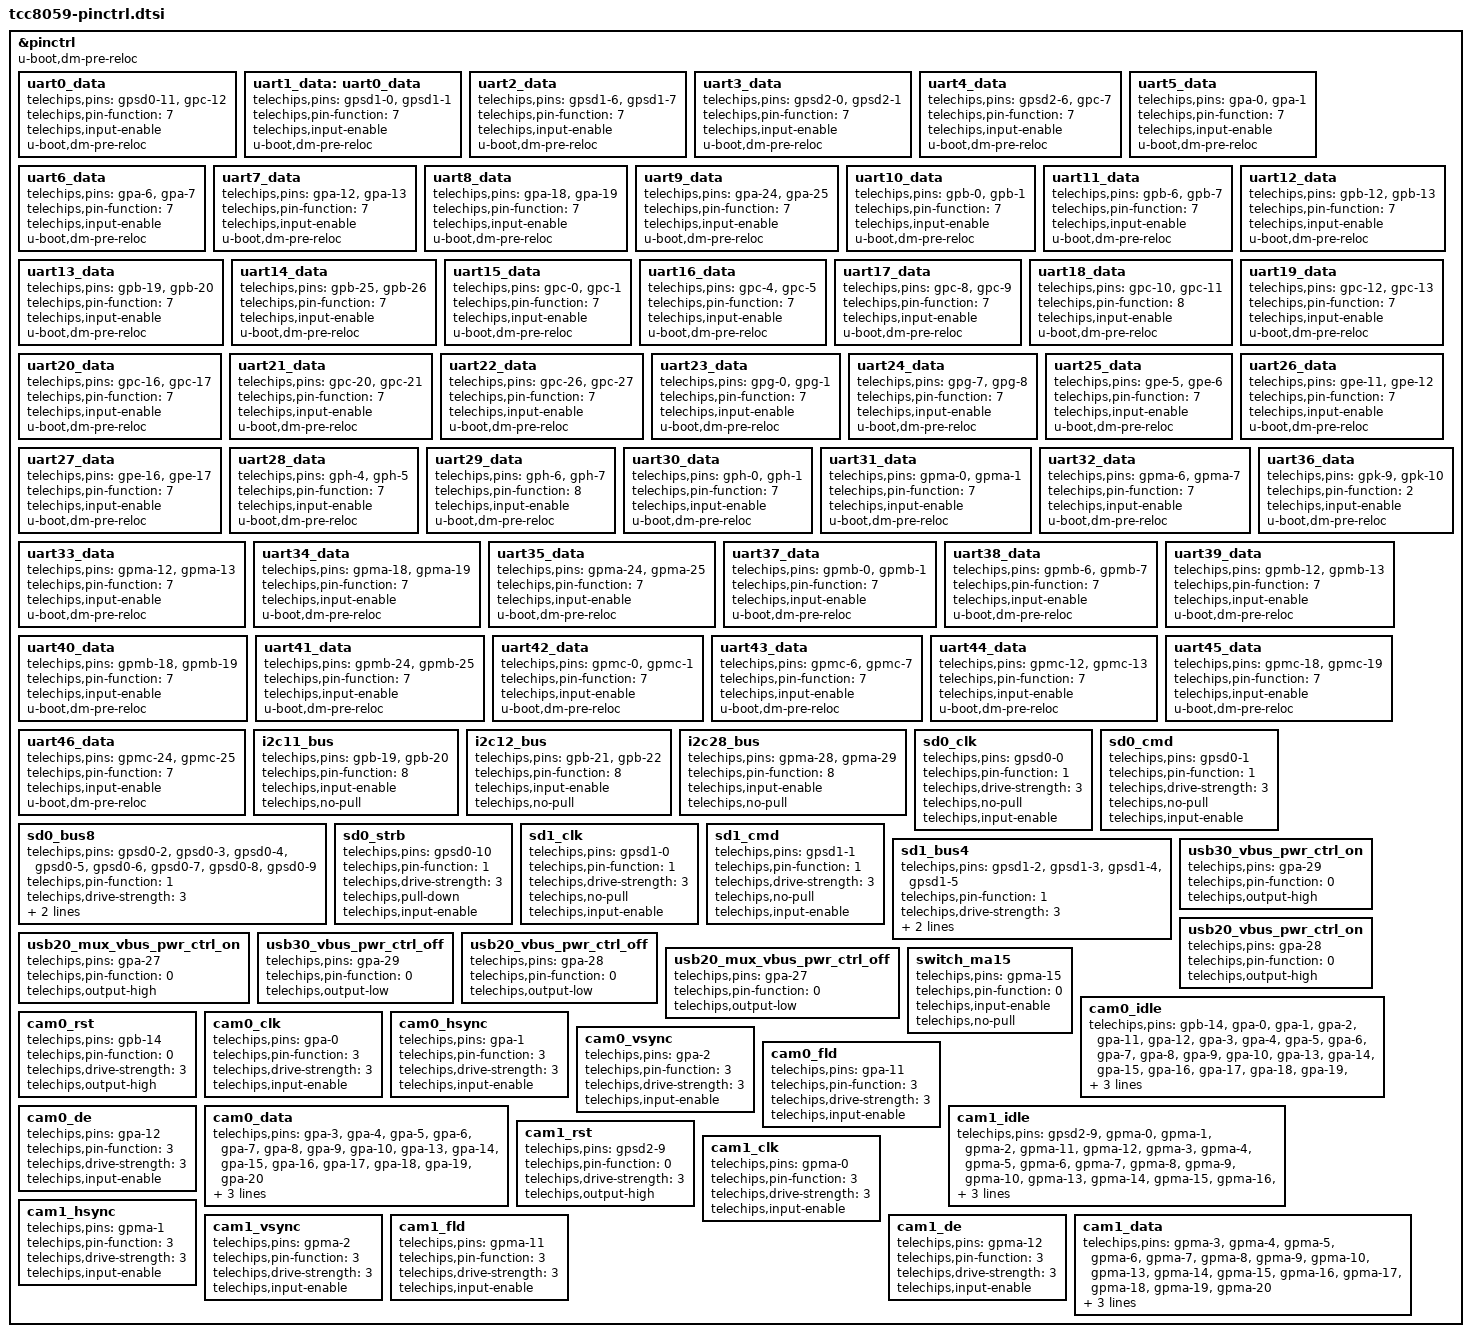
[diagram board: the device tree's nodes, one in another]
// SPDX-License-Identifier: (GPL-2.0-or-later OR MIT)
/*
 * Copyright (C) Telechips Inc.
 */

&pinctrl {
	u-boot,dm-pre-reloc;

	/omit-if-no-ref/
	uart0_data: uart0_data {
		telechips,pins = "gpsd0-11", "gpc-12";
		telechips,pin-function = <7>;
		telechips,input-enable;
		u-boot,dm-pre-reloc;
	};

	/omit-if-no-ref/
	uart1_data: uart0_data {
		telechips,pins = "gpsd1-0", "gpsd1-1";
		telechips,pin-function = <7>;
		telechips,input-enable;
		u-boot,dm-pre-reloc;
	};

	/omit-if-no-ref/
	uart2_data: uart2_data {
		telechips,pins = "gpsd1-6", "gpsd1-7";
		telechips,pin-function = <7>;
		telechips,input-enable;
		u-boot,dm-pre-reloc;
	};

	/omit-if-no-ref/
	uart3_data: uart3_data {
		telechips,pins = "gpsd2-0", "gpsd2-1";
		telechips,pin-function = <7>;
		telechips,input-enable;
		u-boot,dm-pre-reloc;
	};

	/omit-if-no-ref/
	uart4_data: uart4_data {
		telechips,pins = "gpsd2-6", "gpc-7";
		telechips,pin-function = <7>;
		telechips,input-enable;
		u-boot,dm-pre-reloc;
	};

	/omit-if-no-ref/
	uart5_data: uart5_data {
		telechips,pins = "gpa-0", "gpa-1";
		telechips,pin-function = <7>;
		telechips,input-enable;
		u-boot,dm-pre-reloc;
	};

	/omit-if-no-ref/
	uart6_data: uart6_data {
		telechips,pins = "gpa-6", "gpa-7";
		telechips,pin-function = <7>;
		telechips,input-enable;
		u-boot,dm-pre-reloc;
	};

	/omit-if-no-ref/
	uart7_data: uart7_data {
		telechips,pins = "gpa-12", "gpa-13";
		telechips,pin-function = <7>;
		telechips,input-enable;
		u-boot,dm-pre-reloc;
	};

	/omit-if-no-ref/
	uart8_data: uart8_data {
		telechips,pins = "gpa-18", "gpa-19";
		telechips,pin-function = <7>;
		telechips,input-enable;
		u-boot,dm-pre-reloc;
	};

	/omit-if-no-ref/
	uart9_data: uart9_data {
		telechips,pins = "gpa-24", "gpa-25";
		telechips,pin-function = <7>;
		telechips,input-enable;
		u-boot,dm-pre-reloc;
	};

	/omit-if-no-ref/
	uart10_data: uart10_data {
		telechips,pins = "gpb-0", "gpb-1";
		telechips,pin-function = <7>;
		telechips,input-enable;
		u-boot,dm-pre-reloc;
	};

	/omit-if-no-ref/
	uart11_data: uart11_data {
		telechips,pins = "gpb-6", "gpb-7";
		telechips,pin-function = <7>;
		telechips,input-enable;
		u-boot,dm-pre-reloc;
	};

	/omit-if-no-ref/
	uart12_data: uart12_data {
		telechips,pins = "gpb-12", "gpb-13";
		telechips,pin-function = <7>;
		telechips,input-enable;
		u-boot,dm-pre-reloc;
	};

	/omit-if-no-ref/
	uart13_data: uart13_data {
		telechips,pins = "gpb-19", "gpb-20";
		telechips,pin-function = <7>;
		telechips,input-enable;
		u-boot,dm-pre-reloc;
	};

	/omit-if-no-ref/
	uart14_data: uart14_data {
		telechips,pins = "gpb-25", "gpb-26";
		telechips,pin-function = <7>;
		telechips,input-enable;
		u-boot,dm-pre-reloc;
	};

	/omit-if-no-ref/
	uart15_data: uart15_data {
		telechips,pins = "gpc-0", "gpc-1";
		telechips,pin-function = <7>;
		telechips,input-enable;
		u-boot,dm-pre-reloc;
	};

	/omit-if-no-ref/
	uart16_data: uart16_data {
		telechips,pins = "gpc-4", "gpc-5";
		telechips,pin-function = <7>;
		telechips,input-enable;
		u-boot,dm-pre-reloc;
	};

	/omit-if-no-ref/
	uart17_data: uart17_data {
		telechips,pins = "gpc-8", "gpc-9";
		telechips,pin-function = <7>;
		telechips,input-enable;
		u-boot,dm-pre-reloc;
	};

	/omit-if-no-ref/
	uart18_data: uart18_data {
		telechips,pins = "gpc-10", "gpc-11";
		telechips,pin-function = <8>;
		telechips,input-enable;
		u-boot,dm-pre-reloc;
	};

	/omit-if-no-ref/
	uart19_data: uart19_data {
		telechips,pins = "gpc-12", "gpc-13";
		telechips,pin-function = <7>;
		telechips,input-enable;
		u-boot,dm-pre-reloc;
	};

	/omit-if-no-ref/
	uart20_data: uart20_data {
		telechips,pins = "gpc-16", "gpc-17";
		telechips,pin-function = <7>;
		telechips,input-enable;
		u-boot,dm-pre-reloc;
	};

	/omit-if-no-ref/
	uart21_data: uart21_data {
		telechips,pins = "gpc-20", "gpc-21";
		telechips,pin-function = <7>;
		telechips,input-enable;
		u-boot,dm-pre-reloc;
	};

	/omit-if-no-ref/
	uart22_data: uart22_data {
		telechips,pins = "gpc-26", "gpc-27";
		telechips,pin-function = <7>;
		telechips,input-enable;
		u-boot,dm-pre-reloc;
	};

	/omit-if-no-ref/
	uart23_data: uart23_data {
		telechips,pins = "gpg-0", "gpg-1";
		telechips,pin-function = <7>;
		telechips,input-enable;
		u-boot,dm-pre-reloc;
	};

	/omit-if-no-ref/
	uart24_data: uart24_data {
		telechips,pins = "gpg-7", "gpg-8";
		telechips,pin-function = <7>;
		telechips,input-enable;
		u-boot,dm-pre-reloc;
	};

	/omit-if-no-ref/
	uart25_data: uart25_data {
		telechips,pins = "gpe-5", "gpe-6";
		telechips,pin-function = <7>;
		telechips,input-enable;
		u-boot,dm-pre-reloc;
	};

	/omit-if-no-ref/
	uart26_data: uart26_data {
		telechips,pins = "gpe-11", "gpe-12";
		telechips,pin-function = <7>;
		telechips,input-enable;
		u-boot,dm-pre-reloc;
	};

	/omit-if-no-ref/
	uart27_data: uart27_data {
		telechips,pins = "gpe-16", "gpe-17";
		telechips,pin-function = <7>;
		telechips,input-enable;
		u-boot,dm-pre-reloc;
	};

	/omit-if-no-ref/
	uart28_data: uart28_data {
		telechips,pins = "gph-4", "gph-5";
		telechips,pin-function = <7>;
		telechips,input-enable;
		u-boot,dm-pre-reloc;
	};

	/omit-if-no-ref/
	uart29_data: uart29_data {
		telechips,pins = "gph-6", "gph-7";
		telechips,pin-function = <8>;
		telechips,input-enable;
		u-boot,dm-pre-reloc;
	};

	/omit-if-no-ref/
	uart30_data: uart30_data {
		telechips,pins = "gph-0", "gph-1";
		telechips,pin-function = <7>;
		telechips,input-enable;
		u-boot,dm-pre-reloc;
	};

	/omit-if-no-ref/
	uart31_data: uart31_data {
		telechips,pins = "gpma-0", "gpma-1";
		telechips,pin-function = <7>;
		telechips,input-enable;
		u-boot,dm-pre-reloc;
	};

	/omit-if-no-ref/
	uart32_data: uart32_data {
		telechips,pins = "gpma-6", "gpma-7";
		telechips,pin-function = <7>;
		telechips,input-enable;
		u-boot,dm-pre-reloc;
	};

	/omit-if-no-ref/
	uart33_data: uart33_data {
		telechips,pins = "gpma-12", "gpma-13";
		telechips,pin-function = <7>;
		telechips,input-enable;
		u-boot,dm-pre-reloc;
	};

	/omit-if-no-ref/
	uart34_data: uart34_data {
		telechips,pins = "gpma-18", "gpma-19";
		telechips,pin-function = <7>;
		telechips,input-enable;
		u-boot,dm-pre-reloc;
	};

	/omit-if-no-ref/
	uart35_data: uart35_data {
		telechips,pins = "gpma-24", "gpma-25";
		telechips,pin-function = <7>;
		telechips,input-enable;
		u-boot,dm-pre-reloc;
	};

	/omit-if-no-ref/
	uart36_data: uart36_data {
		telechips,pins = "gpk-9", "gpk-10";
		telechips,pin-function = <2>;
		telechips,input-enable;
		u-boot,dm-pre-reloc;
	};

	/omit-if-no-ref/
	uart37_data: uart37_data {
		telechips,pins = "gpmb-0", "gpmb-1";
		telechips,pin-function = <7>;
		telechips,input-enable;
		u-boot,dm-pre-reloc;
	};

	/omit-if-no-ref/
	uart38_data: uart38_data {
		telechips,pins = "gpmb-6", "gpmb-7";
		telechips,pin-function = <7>;
		telechips,input-enable;
		u-boot,dm-pre-reloc;
	};

	/omit-if-no-ref/
	uart39_data: uart39_data {
		telechips,pins = "gpmb-12", "gpmb-13";
		telechips,pin-function = <7>;
		telechips,input-enable;
		u-boot,dm-pre-reloc;
	};

	/omit-if-no-ref/
	uart40_data: uart40_data {
		telechips,pins = "gpmb-18", "gpmb-19";
		telechips,pin-function = <7>;
		telechips,input-enable;
		u-boot,dm-pre-reloc;
	};

	/omit-if-no-ref/
	uart41_data: uart41_data {
		telechips,pins = "gpmb-24", "gpmb-25";
		telechips,pin-function = <7>;
		telechips,input-enable;
		u-boot,dm-pre-reloc;
	};

	/omit-if-no-ref/
	uart42_data: uart42_data {
		telechips,pins = "gpmc-0", "gpmc-1";
		telechips,pin-function = <7>;
		telechips,input-enable;
		u-boot,dm-pre-reloc;
	};

	/omit-if-no-ref/
	uart43_data: uart43_data {
		telechips,pins = "gpmc-6", "gpmc-7";
		telechips,pin-function = <7>;
		telechips,input-enable;
		u-boot,dm-pre-reloc;
	};

	/omit-if-no-ref/
	uart44_data: uart44_data {
		telechips,pins = "gpmc-12", "gpmc-13";
		telechips,pin-function = <7>;
		telechips,input-enable;
		u-boot,dm-pre-reloc;
	};

	/omit-if-no-ref/
	uart45_data: uart45_data {
		telechips,pins = "gpmc-18", "gpmc-19";
		telechips,pin-function = <7>;
		telechips,input-enable;
		u-boot,dm-pre-reloc;
	};

	/omit-if-no-ref/
	uart46_data: uart46_data {
		telechips,pins = "gpmc-24", "gpmc-25";
		telechips,pin-function = <7>;
		telechips,input-enable;
		u-boot,dm-pre-reloc;
	};

	/omit-if-no-ref/
	i2c11_bus: i2c11_bus {
		telechips,pins = "gpb-19", "gpb-20";
		telechips,pin-function = <8>;
		telechips,input-enable;
		telechips,no-pull;
	};

	/omit-if-no-ref/
	i2c12_bus: i2c12_bus {
		telechips,pins = "gpb-21", "gpb-22";
		telechips,pin-function = <8>;
		telechips,input-enable;
		telechips,no-pull;
	};

	/omit-if-no-ref/
	i2c28_bus: i2c28_bus {
		telechips,pins = "gpma-28", "gpma-29";
		telechips,pin-function = <8>;
		telechips,input-enable;
		telechips,no-pull;
	};

	/* GPIO SD0 */
	/omit-if-no-ref/
	sd0_clk: sd0_clk {
		telechips,pins = "gpsd0-0";
		telechips,pin-function = <1>;
		telechips,drive-strength = <3>;
		telechips,no-pull;
		telechips,input-enable;
	};

	/omit-if-no-ref/
	sd0_cmd: sd0_cmd {
		telechips,pins = "gpsd0-1";
		telechips,pin-function = <1>;
		telechips,drive-strength = <3>;
		telechips,no-pull;
		telechips,input-enable;
	};

	/omit-if-no-ref/
	sd0_bus8: sd0_bus8 {
		telechips,pins =  "gpsd0-2", "gpsd0-3", "gpsd0-4", "gpsd0-5",
				  "gpsd0-6", "gpsd0-7", "gpsd0-8", "gpsd0-9";
		telechips,pin-function = <1>;
		telechips,drive-strength = <3>;
		telechips,no-pull;
		telechips,input-enable;
	};

	/omit-if-no-ref/
	sd0_strb: sd0_strb {
		telechips,pins = "gpsd0-10";
		telechips,pin-function = <1>;
		telechips,drive-strength = <3>;
		telechips,pull-down;
		telechips,input-enable;
	};

	/* GPIO SD1 */
	/omit-if-no-ref/
	sd1_clk: sd1_clk {
		telechips,pins = "gpsd1-0";
		telechips,pin-function = <1>;
		telechips,drive-strength = <3>;
		telechips,no-pull;
		telechips,input-enable;
	};

	/omit-if-no-ref/
	sd1_cmd: sd1_cmd {
		telechips,pins = "gpsd1-1";
		telechips,pin-function = <1>;
		telechips,drive-strength = <3>;
		telechips,no-pull;
		telechips,input-enable;
	};

	/omit-if-no-ref/
	sd1_bus4: sd1_bus4 {
		telechips,pins = "gpsd1-2", "gpsd1-3", "gpsd1-4", "gpsd1-5";
		telechips,pin-function = <1>;
		telechips,drive-strength = <3>;
		telechips,no-pull;
		telechips,input-enable;
	};

	/* GPIO USB VBUS */
	/omit-if-no-ref/
	usb30_vbus_pwr_ctrl_on: usb30_vbus_pwr_ctrl_on {
		telechips,pins = "gpa-29";
		telechips,pin-function = <0>;
		telechips,output-high;
	};

	/omit-if-no-ref/
	usb20_vbus_pwr_ctrl_on: usb20_vbus_pwr_ctrl_on {
		telechips,pins = "gpa-28";
		telechips,pin-function = <0>;
		telechips,output-high;
	};

	/omit-if-no-ref/
	usb20_mux_vbus_pwr_ctrl_on: usb20_mux_vbus_pwr_ctrl_on {
		telechips,pins = "gpa-27";
		telechips,pin-function = <0>;
		telechips,output-high;
	};

	/omit-if-no-ref/
	usb30_vbus_pwr_ctrl_off: usb30_vbus_pwr_ctrl_off {
		telechips,pins = "gpa-29";
		telechips,pin-function = <0>;
		telechips,output-low;
	};

	/omit-if-no-ref/
	usb20_vbus_pwr_ctrl_off: usb20_vbus_pwr_ctrl_off {
		telechips,pins = "gpa-28";
		telechips,pin-function = <0>;
		telechips,output-low;
	};

	/omit-if-no-ref/
	usb20_mux_vbus_pwr_ctrl_off: usb20_mux_vbus_pwr_ctrl_off {
		telechips,pins = "gpa-27";
		telechips,pin-function = <0>;
		telechips,output-low;
	};

	/omit-if-no-ref/
	switch_ma15: switch_ma15 {
		telechips,pins = "gpma-15";
		telechips,pin-function = <0>;
		telechips,input-enable;
		telechips,no-pull;
	};

	/omit-if-no-ref/
	cam0_idle: cam0_idle {
		telechips,pins = "gpb-14",
				 "gpa-0",  "gpa-1",  "gpa-2",
				 "gpa-11", "gpa-12",
				 "gpa-3",  "gpa-4",  "gpa-5",  "gpa-6",
				 "gpa-7",  "gpa-8",  "gpa-9",  "gpa-10",
				 "gpa-13", "gpa-14", "gpa-15", "gpa-16",
				 "gpa-17", "gpa-18", "gpa-19", "gpa-20";
		telechips,pin-function = <0>;
		telechips,output-low;
	};

	/omit-if-no-ref/
	cam0_rst: cam0_rst {
		telechips,pins = "gpb-14";
		telechips,pin-function = <0>;
		telechips,drive-strength = <3>;
		telechips,output-high;
	};

	/omit-if-no-ref/
	cam0_clk: cam0_clk {
		telechips,pins = "gpa-0";
		telechips,pin-function = <3>;
		telechips,drive-strength = <3>;
		telechips,input-enable;
	};

	/omit-if-no-ref/
	cam0_hsync: cam0_hsync {
		telechips,pins = "gpa-1";
		telechips,pin-function = <3>;
		telechips,drive-strength = <3>;
		telechips,input-enable;
	};

	/omit-if-no-ref/
	cam0_vsync: cam0_vsync {
		telechips,pins = "gpa-2";
		telechips,pin-function = <3>;
		telechips,drive-strength = <3>;
		telechips,input-enable;
	};

	/omit-if-no-ref/
	cam0_fld: cam0_fld {
		telechips,pins = "gpa-11";
		telechips,pin-function = <3>;
		telechips,drive-strength = <3>;
		telechips,input-enable;
	};

	/omit-if-no-ref/
	cam0_de: cam0_de {
		telechips,pins = "gpa-12";
		telechips,pin-function = <3>;
		telechips,drive-strength = <3>;
		telechips,input-enable;
	};

	/omit-if-no-ref/
	cam0_data: cam0_data {
		telechips,pins = "gpa-3",  "gpa-4",  "gpa-5",  "gpa-6",
				 "gpa-7",  "gpa-8",  "gpa-9",  "gpa-10",
				 "gpa-13", "gpa-14", "gpa-15", "gpa-16",
				 "gpa-17", "gpa-18", "gpa-19", "gpa-20";
		telechips,pin-function = <3>;
		telechips,drive-strength = <3>;
		telechips,input-enable;
	};

	/omit-if-no-ref/
	cam1_idle: cam1_idle {
		telechips,pins = "gpsd2-9",
				 "gpma-0",  "gpma-1",  "gpma-2",
				 "gpma-11", "gpma-12",
				 "gpma-3",  "gpma-4",  "gpma-5",  "gpma-6",
				 "gpma-7",  "gpma-8",  "gpma-9",  "gpma-10",
				 "gpma-13", "gpma-14", "gpma-15", "gpma-16",
				 "gpma-17", "gpma-18", "gpma-19", "gpma-20";
		telechips,pin-function = <0>;
		telechips,output-low;
	};

	/omit-if-no-ref/
	cam1_rst: cam1_rst {
		telechips,pins = "gpsd2-9";
		telechips,pin-function = <0>;
		telechips,drive-strength = <3>;
		telechips,output-high;
	};

	/omit-if-no-ref/
	cam1_clk: cam1_clk {
		telechips,pins = "gpma-0";
		telechips,pin-function = <3>;
		telechips,drive-strength = <3>;
		telechips,input-enable;
	};

	/omit-if-no-ref/
	cam1_hsync: cam1_hsync {
		telechips,pins = "gpma-1";
		telechips,pin-function = <3>;
		telechips,drive-strength = <3>;
		telechips,input-enable;
	};

	/omit-if-no-ref/
	cam1_vsync: cam1_vsync {
		telechips,pins = "gpma-2";
		telechips,pin-function = <3>;
		telechips,drive-strength = <3>;
		telechips,input-enable;
	};

	/omit-if-no-ref/
	cam1_fld: cam1_fld {
		telechips,pins = "gpma-11";
		telechips,pin-function = <3>;
		telechips,drive-strength = <3>;
		telechips,input-enable;
	};

	/omit-if-no-ref/
	cam1_de: cam1_de {
		telechips,pins = "gpma-12";
		telechips,pin-function = <3>;
		telechips,drive-strength = <3>;
		telechips,input-enable;
	};

	/omit-if-no-ref/
	cam1_data: cam1_data {
		telechips,pins = "gpma-3",  "gpma-4",  "gpma-5",  "gpma-6",
				 "gpma-7",  "gpma-8",  "gpma-9",  "gpma-10",
				 "gpma-13", "gpma-14", "gpma-15", "gpma-16",
				 "gpma-17", "gpma-18", "gpma-19", "gpma-20";
		telechips,pin-function = <3>;
		telechips,drive-strength = <3>;
		telechips,input-enable;
	};
};
